AUTOSAR XML (schema 4-0-3)
standard types defined: Boolean, UInt32
package /PATAC/MSM/ComponentTypes
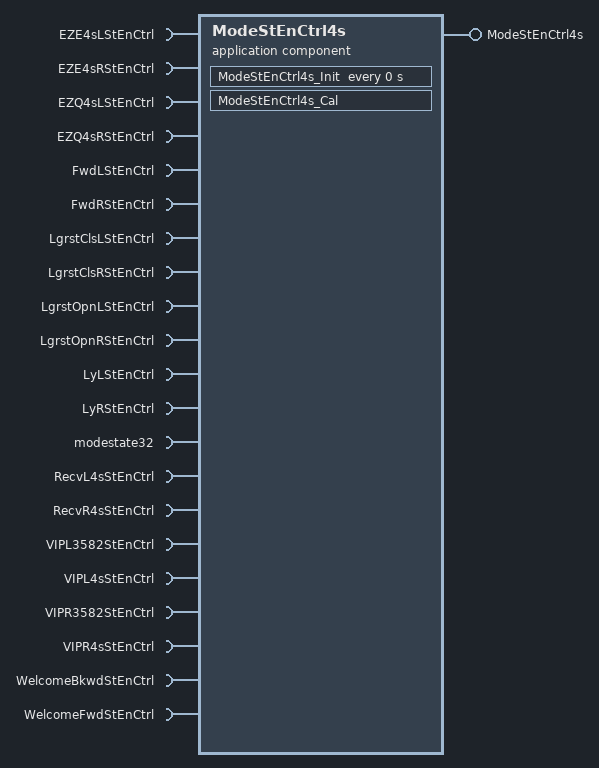
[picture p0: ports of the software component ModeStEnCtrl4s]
  application sw component type ModeStEnCtrl4s
    provide port ModeStEnCtrl4s: server-com-spec{operation=ModeStEnCtrl4s/Cal, queue-length=1}, provided-interface=ModeStEnCtrl4s
    21 x require port:
      EZE4sLStEnCtrl: client-com-spec=EZE4sLStEnCtrl/Cal, required-interface=EZE4sLStEnCtrl
      EZE4sRStEnCtrl: client-com-spec=EZE4sRStEnCtrl/Cal, required-interface=EZE4sRStEnCtrl
      EZQ4sLStEnCtrl: client-com-spec=EZQ4sLStEnCtrl/Cal, required-interface=EZQ4sLStEnCtrl
      EZQ4sRStEnCtrl: client-com-spec=EZQ4sRStEnCtrl/Cal, required-interface=EZQ4sRStEnCtrl
      FwdLStEnCtrl: client-com-spec=FwdLStEnCtrl/Cal, required-interface=FwdLStEnCtrl
      FwdRStEnCtrl: client-com-spec=FwdRStEnCtrl/Cal, required-interface=FwdRStEnCtrl
      LgrstClsLStEnCtrl: client-com-spec=LgrstClsLStEnCtrl/Cal, required-interface=LgrstClsLStEnCtrl
      LgrstClsRStEnCtrl: client-com-spec=LgrstClsRStEnCtrl/Cal, required-interface=LgrstClsRStEnCtrl
      LgrstOpnLStEnCtrl: client-com-spec=LgrstOpnLStEnCtrl/Cal, required-interface=LgrstOpnLStEnCtrl
      LgrstOpnRStEnCtrl: client-com-spec=LgrstOpnRStEnCtrl/Cal, required-interface=LgrstOpnRStEnCtrl
      LyLStEnCtrl: client-com-spec=LyLStEnCtrl/Cal, required-interface=LyLStEnCtrl
      LyRStEnCtrl: client-com-spec=LyRStEnCtrl/Cal, required-interface=LyRStEnCtrl
      modestate32: nonqueued-receiver-com-spec{data-element=Val, filter=data-filter-type=ALWAYS, init-value=0}, required-interface=modestate32
      RecvL4sStEnCtrl: client-com-spec=RecvL4sStEnCtrl/Cal, required-interface=RecvL4sStEnCtrl
      RecvR4sStEnCtrl: client-com-spec=RecvR4sStEnCtrl/Cal, required-interface=RecvR4sStEnCtrl
      VIPL3582StEnCtrl: client-com-spec=VIPL3582StEnCtrl/Cal, required-interface=VIPL3582StEnCtrl
      VIPL4sStEnCtrl: client-com-spec=VIPL4sStEnCtrl/Cal, required-interface=VIPL4sStEnCtrl
      VIPR3582StEnCtrl: client-com-spec=VIPR3582StEnCtrl/Cal, required-interface=VIPR3582StEnCtrl
      VIPR4sStEnCtrl: client-com-spec=VIPR4sStEnCtrl/Cal, required-interface=VIPR4sStEnCtrl
      WelcomeBkwdStEnCtrl: client-com-spec=WelcomeBkwdStEnCtrl/Cal, required-interface=WelcomeBkwdStEnCtrl
      WelcomeFwdStEnCtrl: client-com-spec=WelcomeFwdStEnCtrl/Cal, required-interface=WelcomeFwdStEnCtrl
    behavior ModeStEnCtrl4s_InternalBehavior
      operation invoked event OIT_ModeStEnCtrl4s_Cal_ModeStEnCtrl4s_Cal: start-on-event=ModeStEnCtrl4s_Cal, operation=ModeStEnCtrl4s.Cal
      timing event ModeStEnCtrl4s_InitEvent: start-on-event=ModeStEnCtrl4s_Init, period=0
      runnable ModeStEnCtrl4s_Cal
        data-receive-point-by-arguments:
          access REC_modestate32_Val: accessed-variable=modestate32.Val
        20 x sync call, all with timeout=0:
          SC_EZE4sLStEnCtrl_Cal: operation=EZE4sLStEnCtrl.Cal
          SC_EZE4sRStEnCtrl_Cal: operation=EZE4sRStEnCtrl.Cal
          SC_EZQ4sLStEnCtrl_Cal: operation=EZQ4sLStEnCtrl.Cal
          SC_EZQ4sRStEnCtrl_Cal: operation=EZQ4sRStEnCtrl.Cal
          SC_FwdLStEnCtrl_Cal: operation=FwdLStEnCtrl.Cal
          SC_FwdRStEnCtrl_Cal: operation=FwdRStEnCtrl.Cal
          SC_LgrstClsLStEnCtrl_Cal: operation=LgrstClsLStEnCtrl.Cal
          SC_LgrstClsRStEnCtrl_Cal: operation=LgrstClsRStEnCtrl.Cal
          SC_LgrstOpnLStEnCtrl_Cal: operation=LgrstOpnLStEnCtrl.Cal
          SC_LgrstOpnRStEnCtrl_Cal: operation=LgrstOpnRStEnCtrl.Cal
          SC_LyLStEnCtrl_Cal: operation=LyLStEnCtrl.Cal
          SC_LyRStEnCtrl_Cal: operation=LyRStEnCtrl.Cal
          SC_RecvL4sStEnCtrl_Cal: operation=RecvL4sStEnCtrl.Cal
          SC_RecvR4sStEnCtrl_Cal: operation=RecvR4sStEnCtrl.Cal
          SC_VIPL3582StEnCtrl_Cal: operation=VIPL3582StEnCtrl.Cal
          SC_VIPL4sStEnCtrl_Cal: operation=VIPL4sStEnCtrl.Cal
          SC_VIPR3582StEnCtrl_Cal: operation=VIPR3582StEnCtrl.Cal
          SC_VIPR4sStEnCtrl_Cal: operation=VIPR4sStEnCtrl.Cal
          SC_WelcomeBkwdStEnCtrl_Cal: operation=WelcomeBkwdStEnCtrl.Cal
          SC_WelcomeFwdStEnCtrl_Cal: operation=WelcomeFwdStEnCtrl.Cal
      runnable ModeStEnCtrl4s_Init
  swc implementation ModeStEnCtrl4s_Implementation: behavior=ModeStEnCtrl4s_InternalBehavior
    code-descriptors:
      code Default: artifact-descriptors=autosar-engineering-object={short-label=Default, category=SWSRC}
package /PATAC/MSM/ModeAdjust/PortInterface
  21 x client server interface:
    EZE4sLStEnCtrl
      operation Cal
    EZE4sRStEnCtrl
      operation Cal
    EZQ4sLStEnCtrl
      operation Cal
        arg ResetCond: type=DataTypes/Boolean, direction=IN, server-argument-impl-policy=USE-ARGUMENT-TYPE
    EZQ4sRStEnCtrl
      operation Cal
        arg ResetCond: type=DataTypes/Boolean, direction=IN, server-argument-impl-policy=USE-ARGUMENT-TYPE
    FwdLStEnCtrl
      operation Cal
    FwdRStEnCtrl
      operation Cal
    LgrstClsLStEnCtrl
      operation Cal
    LgrstClsRStEnCtrl
      operation Cal
    LgrstOpnLStEnCtrl
      operation Cal
    LgrstOpnRStEnCtrl
      operation Cal
    LyLStEnCtrl
      operation Cal
    LyRStEnCtrl
      operation Cal
    ModeStEnCtrl4s
      operation Cal
    RecvL4sStEnCtrl
      operation Cal
    RecvR4sStEnCtrl
      operation Cal
    VIPL3582StEnCtrl
      operation Cal
    VIPL4sStEnCtrl
      operation Cal
    VIPR3582StEnCtrl
      operation Cal
        arg FirstTrig: type=DataTypes/Boolean, direction=IN, server-argument-impl-policy=USE-ARGUMENT-TYPE
    VIPR4sStEnCtrl
      operation Cal
    WelcomeBkwdStEnCtrl
      operation Cal
    WelcomeFwdStEnCtrl
      operation Cal
  sender receiver interface modestate32: invalidation-policy{data-element=Val, handle-invalid=DONT-INVALIDATE}
    data Val: type=UInt32
